VERSION ""

NS_ :

BS_:

BU_:

BO_ 3221225472 VECTOR__INDEPENDENT_SIG_MSG: 0 Vector__XXX
 SG_ temp_x : 0|16@1+ (1,0) [0|65535] "null" Vector__XXX

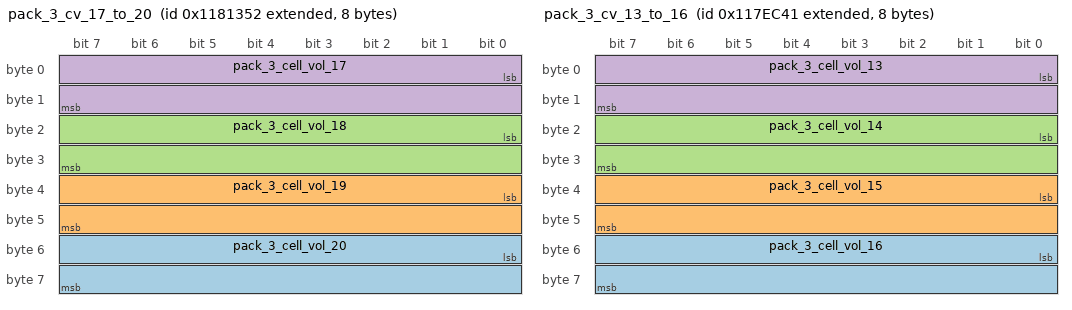
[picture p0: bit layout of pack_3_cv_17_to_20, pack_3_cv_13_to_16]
BO_ 2165838674 pack_3_cv_17_to_20: 8 Vector__XXX
 SG_ pack_3_cell_vol_20 : 48|16@1+ (1,0) [0|65535] "mv" Vector__XXX
 SG_ pack_3_cell_vol_19 : 32|16@1+ (1,0) [0|65535] "mv" Vector__XXX
 SG_ pack_3_cell_vol_18 : 16|16@1+ (1,0) [0|65535] "mv" Vector__XXX
 SG_ pack_3_cell_vol_17 : 0|16@1+ (1,0) [0|65535] "mv" Vector__XXX

BO_ 2165828673 pack_3_cv_13_to_16: 8 Vector__XXX
 SG_ pack_3_cell_vol_16 : 48|16@1+ (1,0) [0|65535] "mv" Vector__XXX
 SG_ pack_3_cell_vol_15 : 32|16@1+ (1,0) [0|65535] "mv" Vector__XXX
 SG_ pack_3_cell_vol_14 : 16|16@1+ (1,0) [0|65535] "mv" Vector__XXX
 SG_ pack_3_cell_vol_13 : 0|16@1+ (1,0) [0|65535] "mv" Vector__XXX

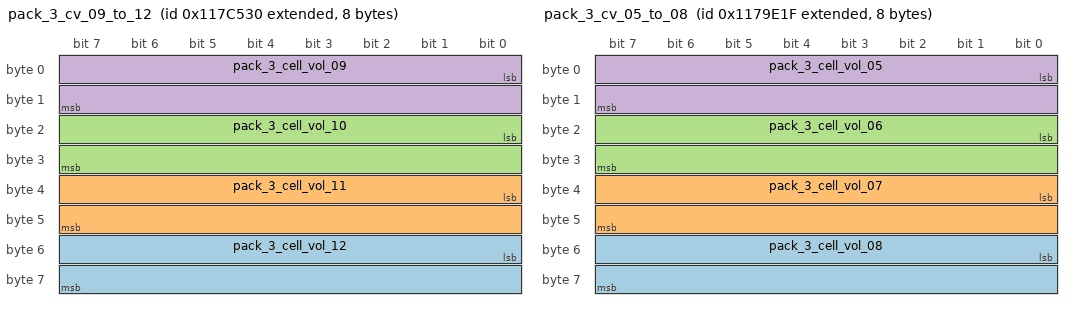
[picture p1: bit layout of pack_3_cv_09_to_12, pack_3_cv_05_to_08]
BO_ 2165818672 pack_3_cv_09_to_12: 8 Vector__XXX
 SG_ pack_3_cell_vol_12 : 48|16@1+ (1,0) [0|65535] "mv" Vector__XXX
 SG_ pack_3_cell_vol_11 : 32|16@1+ (1,0) [0|65535] "mv" Vector__XXX
 SG_ pack_3_cell_vol_10 : 16|16@1+ (1,0) [0|65535] "mv" Vector__XXX
 SG_ pack_3_cell_vol_09 : 0|16@1+ (1,0) [0|65535] "mv" Vector__XXX

BO_ 2165808671 pack_3_cv_05_to_08: 8 Vector__XXX
 SG_ pack_3_cell_vol_08 : 48|16@1+ (1,0) [0|65535] "mv" Vector__XXX
 SG_ pack_3_cell_vol_07 : 32|16@1+ (1,0) [0|65535] "mv" Vector__XXX
 SG_ pack_3_cell_vol_06 : 16|16@1+ (1,0) [0|65535] "mv" Vector__XXX
 SG_ pack_3_cell_vol_05 : 0|16@1+ (1,0) [0|65535] "mv" Vector__XXX

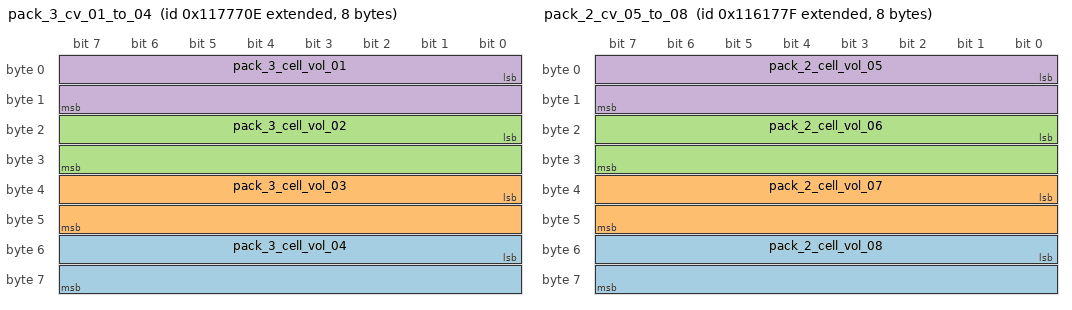
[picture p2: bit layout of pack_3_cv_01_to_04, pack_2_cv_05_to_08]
BO_ 2165798670 pack_3_cv_01_to_04: 8 Vector__XXX
 SG_ pack_3_cell_vol_04 : 48|16@1+ (1,0) [0|65535] "mv" Vector__XXX
 SG_ pack_3_cell_vol_03 : 32|16@1+ (1,0) [0|65535] "mv" Vector__XXX
 SG_ pack_3_cell_vol_02 : 16|16@1+ (1,0) [0|65535] "mv" Vector__XXX
 SG_ pack_3_cell_vol_01 : 0|16@1+ (1,0) [0|65535] "mv" Vector__XXX

BO_ 2165708671 pack_2_cv_05_to_08: 8 Vector__XXX
 SG_ pack_2_cell_vol_08 : 48|16@1+ (1,0) [0|65535] "mv" Vector__XXX
 SG_ pack_2_cell_vol_07 : 32|16@1+ (1,0) [0|65535] "mv" Vector__XXX
 SG_ pack_2_cell_vol_06 : 16|16@1+ (1,0) [0|65535] "mv" Vector__XXX
 SG_ pack_2_cell_vol_05 : 0|16@1+ (1,0) [0|65535] "mv" Vector__XXX

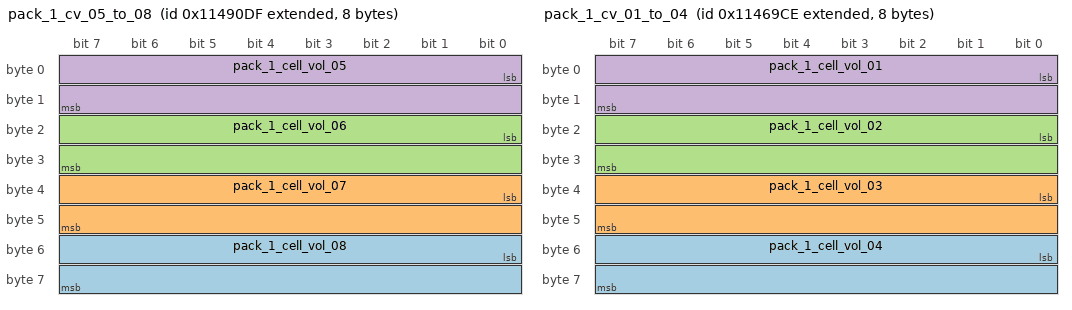
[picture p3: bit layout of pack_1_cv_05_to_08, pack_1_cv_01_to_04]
BO_ 2165608671 pack_1_cv_05_to_08: 8 Vector__XXX
 SG_ pack_1_cell_vol_08 : 48|16@1+ (1,0) [0|65535] "mv" Vector__XXX
 SG_ pack_1_cell_vol_07 : 32|16@1+ (1,0) [0|65535] "mv" Vector__XXX
 SG_ pack_1_cell_vol_06 : 16|16@1+ (1,0) [0|65535] "mv" Vector__XXX
 SG_ pack_1_cell_vol_05 : 0|16@1+ (1,0) [0|65535] "mv" Vector__XXX

BO_ 2165598670 pack_1_cv_01_to_04: 8 Vector__XXX
 SG_ pack_1_cell_vol_04 : 48|16@1+ (1,0) [0|65535] "mv" Vector__XXX
 SG_ pack_1_cell_vol_03 : 32|16@1+ (1,0) [0|65535] "mv" Vector__XXX
 SG_ pack_1_cell_vol_02 : 16|16@1+ (1,0) [0|65535] "mv" Vector__XXX
 SG_ pack_1_cell_vol_01 : 0|16@1+ (1,0) [0|65535] "mv" Vector__XXX

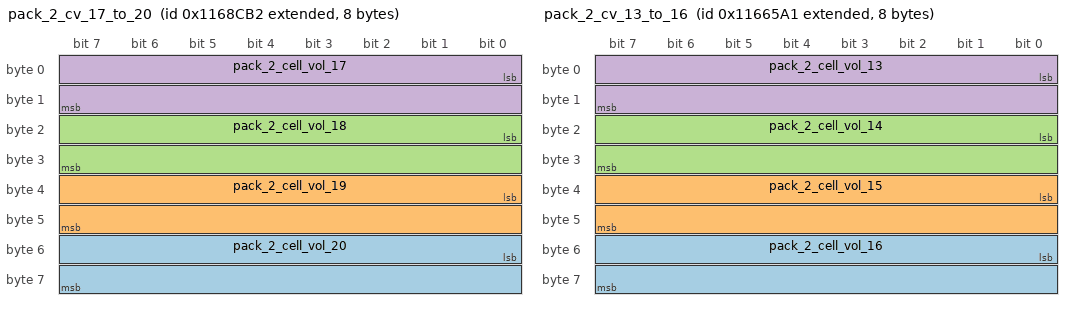
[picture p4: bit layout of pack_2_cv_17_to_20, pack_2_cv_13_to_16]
BO_ 2165738674 pack_2_cv_17_to_20: 8 Vector__XXX
 SG_ pack_2_cell_vol_20 : 48|16@1+ (1,0) [0|65535] "mv" Vector__XXX
 SG_ pack_2_cell_vol_19 : 32|16@1+ (1,0) [0|65535] "mv" Vector__XXX
 SG_ pack_2_cell_vol_18 : 16|16@1+ (1,0) [0|65535] "mv" Vector__XXX
 SG_ pack_2_cell_vol_17 : 0|16@1+ (1,0) [0|65535] "mv" Vector__XXX

BO_ 2165728673 pack_2_cv_13_to_16: 8 Vector__XXX
 SG_ pack_2_cell_vol_16 : 48|16@1+ (1,0) [0|65535] "mv" Vector__XXX
 SG_ pack_2_cell_vol_15 : 32|16@1+ (1,0) [0|65535] "mv" Vector__XXX
 SG_ pack_2_cell_vol_14 : 16|16@1+ (1,0) [0|65535] "mv" Vector__XXX
 SG_ pack_2_cell_vol_13 : 0|16@1+ (1,0) [0|65535] "mv" Vector__XXX

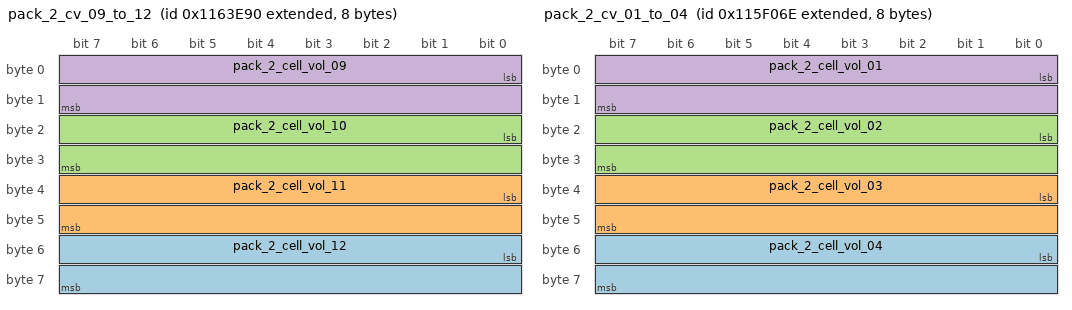
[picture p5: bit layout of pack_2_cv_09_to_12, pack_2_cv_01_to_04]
BO_ 2165718672 pack_2_cv_09_to_12: 8 Vector__XXX
 SG_ pack_2_cell_vol_12 : 48|16@1+ (1,0) [0|65535] "mv" Vector__XXX
 SG_ pack_2_cell_vol_11 : 32|16@1+ (1,0) [0|65535] "mv" Vector__XXX
 SG_ pack_2_cell_vol_10 : 16|16@1+ (1,0) [0|65535] "mv" Vector__XXX
 SG_ pack_2_cell_vol_09 : 0|16@1+ (1,0) [0|65535] "mv" Vector__XXX

BO_ 2165698670 pack_2_cv_01_to_04: 8 Vector__XXX
 SG_ pack_2_cell_vol_04 : 48|16@1+ (1,0) [0|65535] "mv" Vector__XXX
 SG_ pack_2_cell_vol_03 : 32|16@1+ (1,0) [0|65535] "mv" Vector__XXX
 SG_ pack_2_cell_vol_02 : 16|16@1+ (1,0) [0|65535] "mv" Vector__XXX
 SG_ pack_2_cell_vol_01 : 0|16@1+ (1,0) [0|65535] "mv" Vector__XXX

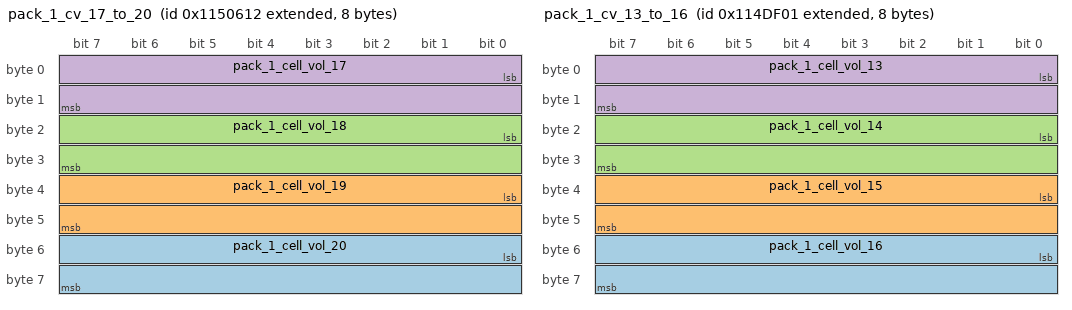
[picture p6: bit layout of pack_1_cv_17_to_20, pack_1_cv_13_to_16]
BO_ 2165638674 pack_1_cv_17_to_20: 8 Vector__XXX
 SG_ pack_1_cell_vol_20 : 48|16@1+ (1,0) [0|65535] "mv" Vector__XXX
 SG_ pack_1_cell_vol_19 : 32|16@1+ (1,0) [0|65535] "mv" Vector__XXX
 SG_ pack_1_cell_vol_18 : 16|16@1+ (1,0) [0|65535] "mv" Vector__XXX
 SG_ pack_1_cell_vol_17 : 0|16@1+ (1,0) [0|65535] "mv" Vector__XXX

BO_ 2165628673 pack_1_cv_13_to_16: 8 Vector__XXX
 SG_ pack_1_cell_vol_16 : 48|16@1+ (1,0) [0|65535] "mv" Vector__XXX
 SG_ pack_1_cell_vol_15 : 32|16@1+ (1,0) [0|65535] "mv" Vector__XXX
 SG_ pack_1_cell_vol_14 : 16|16@1+ (1,0) [0|65535] "mv" Vector__XXX
 SG_ pack_1_cell_vol_13 : 0|16@1+ (1,0) [0|65535] "mv" Vector__XXX

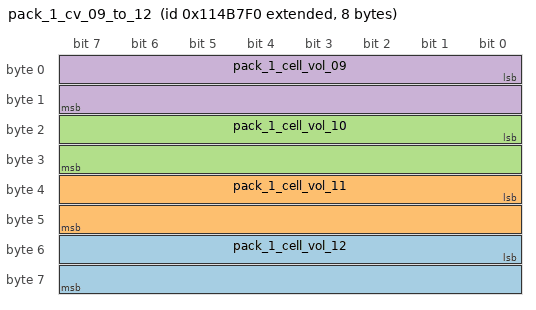
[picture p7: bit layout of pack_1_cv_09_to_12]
BO_ 2165618672 pack_1_cv_09_to_12: 8 Vector__XXX
 SG_ pack_1_cell_vol_12 : 48|16@1+ (1,0) [0|65535] "mv" Vector__XXX
 SG_ pack_1_cell_vol_11 : 32|16@1+ (1,0) [0|65535] "mv" Vector__XXX
 SG_ pack_1_cell_vol_10 : 16|16@1+ (1,0) [0|65535] "mv" Vector__XXX
 SG_ pack_1_cell_vol_09 : 0|16@1+ (1,0) [0|65535] "mv" Vector__XXX

CM_ BO_ 3221225472 "This is a message for not used signals, created by Vector CANdb++ DBC OLE DB Provider.";
CM_ SG_ 3221225472 temp_x "温度信号";
CM_ SG_ 2165598670 pack_1_cell_vol_02 "1号电池组02号电芯的电压值";
CM_ SG_ 2165598670 pack_1_cell_vol_01 "1号电池组01号电芯的电压值";
BA_DEF_ SG_  "GenSigSendType" ENUM  "Cyclic","OnWrite","OnWriteWithRepetition","OnChange","OnChangeWithRepetition","IfActive","IfActiveWithRepetition","NoSigSendType";
BA_DEF_ BO_  "GenMsgSendType" ENUM  "Cyclic","not_used","not_used","not_used","not_used","Cyclic","not_used","IfActive","NoMsgSendType";
BA_DEF_  "DBName" STRING ;
BA_DEF_  "BusType" STRING ;
BA_DEF_DEF_  "GenSigSendType" "Cyclic";
BA_DEF_DEF_  "GenMsgSendType" "NoMsgSendType";
BA_DEF_DEF_  "DBName" "";
BA_DEF_DEF_  "BusType" "CAN";
BA_ "DBName" "BMS_BUS";
